# CY8C4246AZI_L445 register map
File version: 0.1
PSoC 4200L
Registers are 32-bit, read-write, no defined reset value unless marked. A register's access mark holds for its fields unless they carry their own. Offsets are from the block's base; lines under a group give offsets from that group; [hi:lo] are bit positions; {n}, {i} and the like mark numbered series; 'fields as' and 'values as' point back to an identical list; <NAME> marks a mode.

## Memory map
0x00000000 SPI — Serial Communication Block
0x00000000 USB — USBFS
0x00000000 MIDI1_UART — UART
0x00000000 UART — Serial Communication Block
0x00000000 DMAC — DMAC Registers
0x00000000 CC_Timer
0x00000000 CodecI2CM — Serial Communication Block
0x00000000 I2S
0x00000000 TxByteCounter
0x00000000 AudioClkSel
0x00000000 ADC — Sequencing SAR ADC

## MIDI1_UART — UART
Base 0x00000000
0x400F0021 RX_MIDI1_UART_RX_ADDRESS1 8-bit — RX Address1 Register
0x400F0031 RX_MIDI1_UART_RX_ADDRESS2 8-bit — RX Address2 Register
0x400F0041 RX_MIDI1_UART_RX_DATA 8-bit — RX Data Register
0x400F0045 TX_MIDI1_UART_TX_DATA 8-bit — TX Data Register
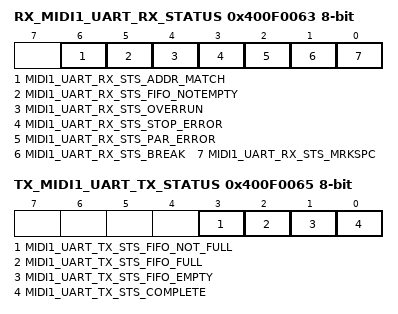
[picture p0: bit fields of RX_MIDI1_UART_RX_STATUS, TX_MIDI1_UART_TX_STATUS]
0x400F0063 RX_MIDI1_UART_RX_STATUS 8-bit — RX status register
  [6] MIDI1_UART_RX_STS_ADDR_MATCH ro, [5] MIDI1_UART_RX_STS_FIFO_NOTEMPTY ro, [4] MIDI1_UART_RX_STS_OVERRUN ro, [3] MIDI1_UART_RX_STS_STOP_ERROR ro, [2] MIDI1_UART_RX_STS_PAR_ERROR ro, [1] MIDI1_UART_RX_STS_BREAK ro, [0] MIDI1_UART_RX_STS_MRKSPC ro
0x400F0065 TX_MIDI1_UART_TX_STATUS 8-bit — TX status register
  [3] MIDI1_UART_TX_STS_FIFO_NOT_FULL ro, [2] MIDI1_UART_TX_STS_FIFO_FULL ro, [1] MIDI1_UART_TX_STS_FIFO_EMPTY ro, [0] MIDI1_UART_TX_STS_COMPLETE ro

## CC_Timer
Base 0x00000000
0x40200108 COUNTER — Current counter value
0x4020010C CC — Compare / capture value
0x40200110 CC_BUF — Compare / capture buffer value
0x40200114 PERIOD — Period value
0x40200118 PERIOD_BUF — Period buffer value

## I2S
Base 0x00000000
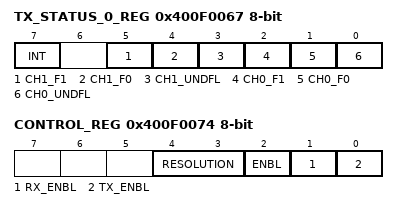
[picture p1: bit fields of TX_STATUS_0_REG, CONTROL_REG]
0x400F0067 TX_STATUS_0_REG 8-bit
  [7] INT ro — Interrupt bit
  [5] CH1_F1 ro — Stereo channel 1 FIFO 1 state
    0=FULL; 1=NOT_FULL
  [4] CH1_F0 ro — Stereo channel 1 FIFO 0 state
    0=FULL; 1=NOT_FULL
  [3] CH1_UNDFL ro — Stereo channel 1 FIFO underflow
    0=NO_UNDERFLOW; 1=UNDERFLOW
  [2] CH0_F1 ro — Stereo channel 0 FIFO 1 state
    0=FULL; 1=NOT_FULL
  [1] CH0_F0 ro — Stereo channel 0 FIFO 0 state
    0=FULL; 1=NOT_FULL
  [0] CH0_UNDFL ro — Stereo channel 0 FIFO underflow
    0=NO_UNDERFLOW; 1=UNDERFLOW
0x400F0074 CONTROL_REG 8-bit
  [4:3] RESOLUTION — Specifies data bits value. Applicable only if dynamic bit resolution is selected.
    0=Cy8_BIT; 1=Cy16_BIT; 2=Cy24_BIT; 3=Cy32_BIT
  [2] ENBL — Starts the generation of the WS and SCK outputs.
    1=ENABLED; 0=DISABLED
  [1] RX_ENBL — Enables Rx direction. Applicable only if Rx direction presents for the component.
    1=ENABLED; 0=DISABLED
  [0] TX_ENBL — Enables Tx direction. Applicable only if Tx direction presents for the component.
    1=ENABLED; 0=DISABLED

## TxByteCounter
Base 0x00000000
0x40200148 COUNTER — Current counter value
0x4020014C CC — Compare / capture value
0x40200150 CC_BUF — Compare / capture buffer value
0x40200154 PERIOD — Period value
0x40200158 PERIOD_BUF — Period buffer value

## AudioClkSel
Base 0x00000000
0x400F0070 AudioClkSel_CONTROL_REG 8-bit
